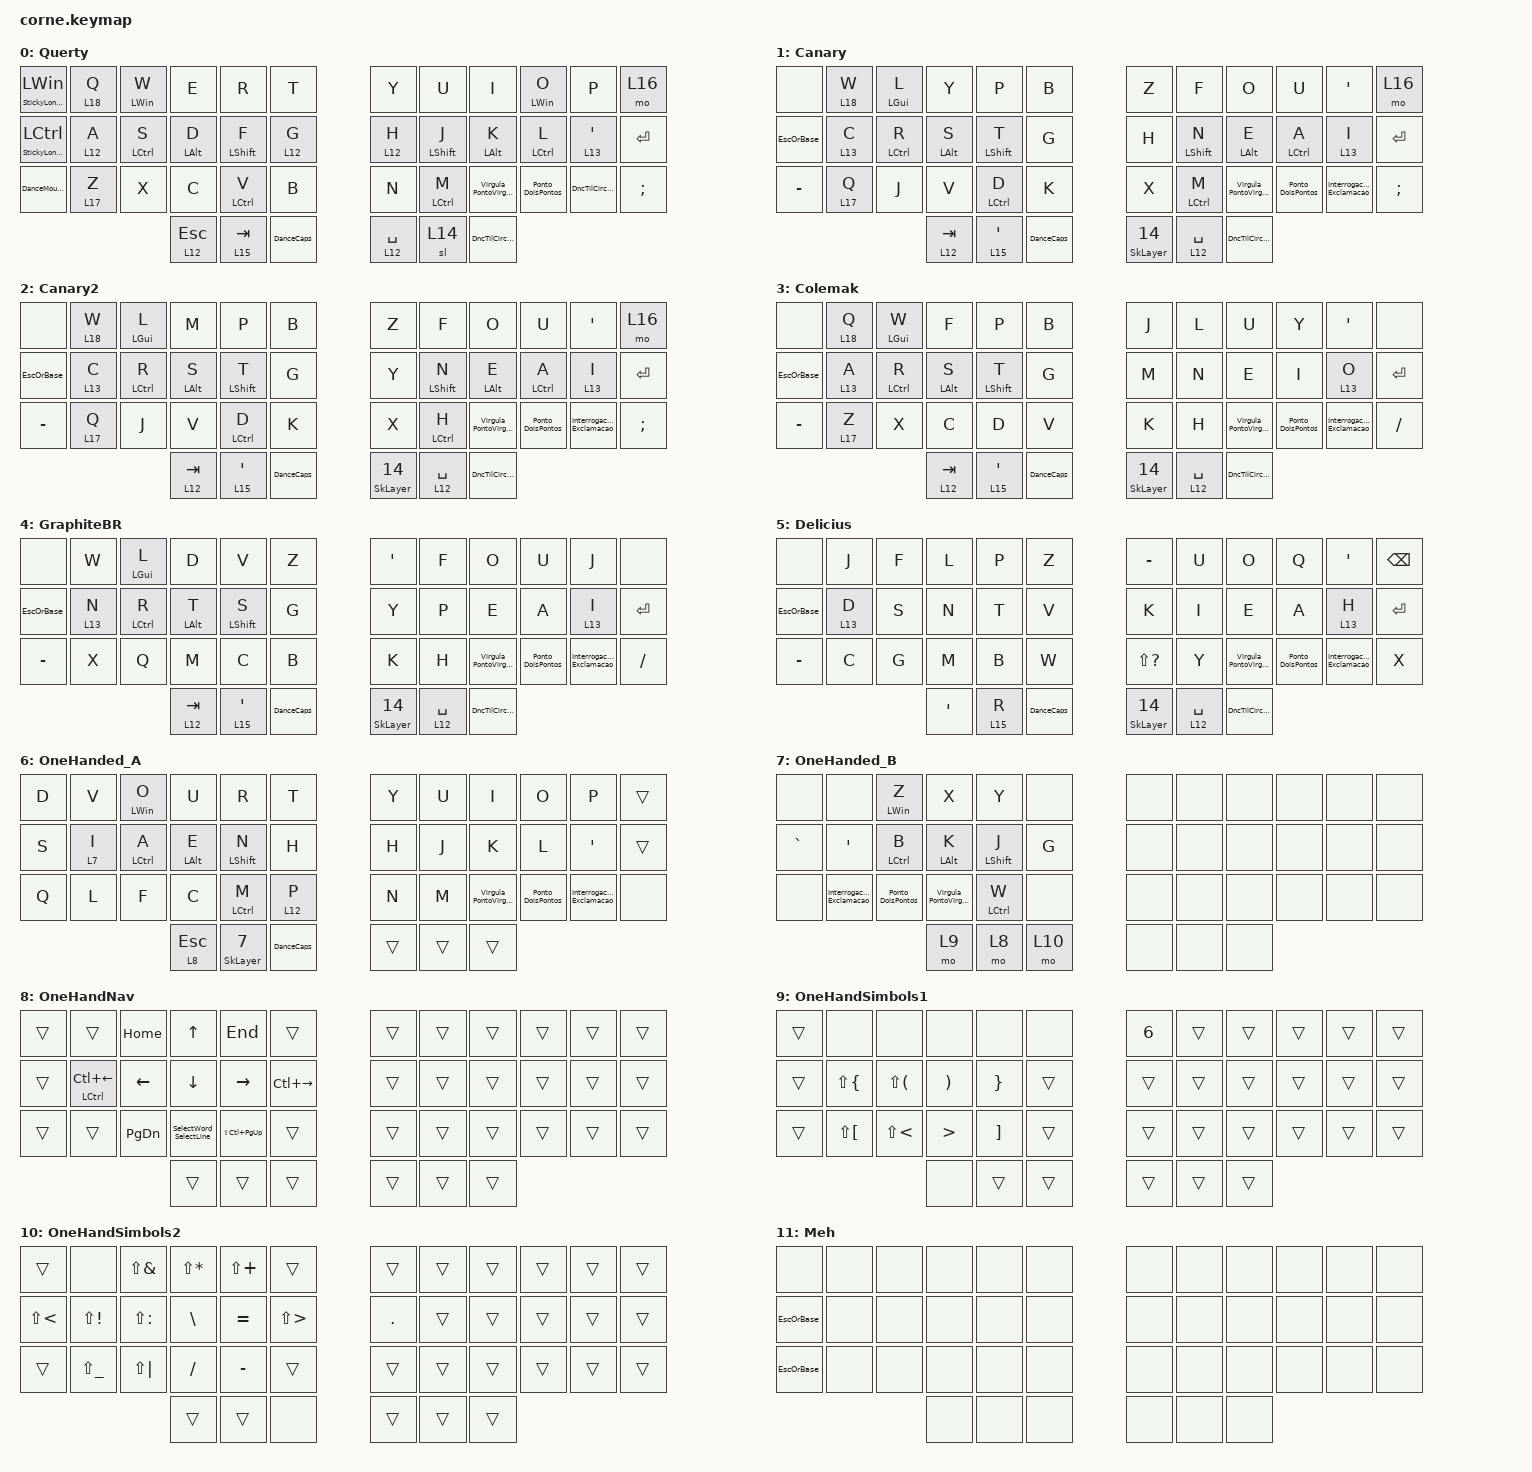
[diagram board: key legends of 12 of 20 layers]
/*
 * Copyright (c) 2020 The ZMK Contributors
 *
 * SPDX-License-Identifier: MIT
 */

#include <dt-bindings/zmk/mouse.h>
#include <behaviors.dtsi>
#include <dt-bindings/zmk/bt.h>
#include <dt-bindings/zmk/keys.h>
#include <dt-bindings/zmk/outputs.h>
#include <dt-bindings/zmk/pointing.h>

/ {
    macros {
        select_line: select_line {
            compatible = "zmk,behavior-macro";
            #binding-cells = <0>;
            bindings = <&kp HOME &kp LS(END)>;
            label = "SELECT_LINE";
            wait-ms = <10>;
            tap-ms = <10>;
        };

        select_left: select_left {
            compatible = "zmk,behavior-macro";
            #binding-cells = <0>;
            bindings = <&kp LC(LEFT) &kp LC(LEFT) &kp LC(LS(RIGHT))>;
            label = "SELECT_LEFT";
            wait-ms = <10>;
            tap-ms = <10>;
        };

        select_right: select_right {
            compatible = "zmk,behavior-macro";
            #binding-cells = <0>;
            bindings = <&kp LC(RIGHT) &kp LC(RIGHT) &kp LC(LS(LEFT))>;
            label = "SELECT_RIGHT";
            wait-ms = <10>;
            tap-ms = <10>;
        };

        Enter_Abaixo: Enter_Abaixo {
            compatible = "zmk,behavior-macro";
            #binding-cells = <0>;
            bindings = <&kp END &kp ENTER>;
            label = "ENTER_ABAIXO";
            wait-ms = <1>;
            tap-ms = <1>;
        };

        Enter_Acima: Enter_Acima {
            compatible = "zmk,behavior-macro";
            #binding-cells = <0>;
            bindings = <&kp HOME &kp ENTER &kp UP_ARROW>;
            label = "ENTER_ACIMA";
            wait-ms = <1>;
            tap-ms = <1>;
        };

        PureCaret: PureCaret {
            compatible = "zmk,behavior-macro";
            #binding-cells = <0>;
            bindings = <&kp CARET &kp SPACE>;
            label = "PURECARET";
            wait-ms = <10>;
            tap-ms = <30>;
        };

        PureSqt: PureSqt {
            compatible = "zmk,behavior-macro";
            #binding-cells = <0>;
            bindings = <&kp SQT &kp SPACE>;
            label = "PURESQT";
            wait-ms = <10>;
            tap-ms = <30>;
        };

        PureQuot: PureQuot {
            compatible = "zmk,behavior-macro";
            #binding-cells = <0>;
            bindings = <&kp DOUBLE_QUOTES &kp SPACE>;
            label = "PUREQUOT";
            wait-ms = <10>;
            tap-ms = <30>;
        };

        PureGrave: PureGrave {
            compatible = "zmk,behavior-macro";
            #binding-cells = <0>;
            bindings = <&kp GRAVE &kp SPACE>;
            label = "PUREGRAVE";
            wait-ms = <10>;
            tap-ms = <30>;
        };

        NumFacil: Easy4Numbers {
            compatible = "zmk,behavior-macro";
            #binding-cells = <0>;
            bindings = <&kp N3 &kp N5 &kp N1 &kp N9>;
            label = "EASY4NUMBERS";
            wait-ms = <10>;
            tap-ms = <30>;
        };

        NumMedio: NumbersMedium {
            compatible = "zmk,behavior-macro";
            #binding-cells = <0>;
            bindings = <&kp N9 &kp N1 &kp N3 &kp N7 &kp N4 &kp N5>;
            label = "NUMBERSMEDIUM";
            wait-ms = <10>;
            tap-ms = <30>;
        };

        NumDificil: NumbersHard {
            compatible = "zmk,behavior-macro";
            #binding-cells = <0>;
            bindings = <&kp N1 &kp N3 &kp N5 &kp N9 &kp N7 &kp N5 &kp N6 &kp N4>;
            label = "NUMBERSHARD";
            wait-ms = <10>;
            tap-ms = <30>;
        };

        AlfaNumFacil: AlfaNumFacil {
            compatible = "zmk,behavior-macro";
            #binding-cells = <0>;
            bindings = <&kp LS(Z) &kp J &kp GRAVE &kp N6 &kp N1 &kp N9>;
            label = "ALFANUMFACIL";
            wait-ms = <10>;
            tap-ms = <30>;
        };

        AlfaNumMedio: AlfaNumMedio {
            compatible = "zmk,behavior-macro";
            #binding-cells = <0>;
            bindings = <&kp Y &kp N1 &kp S &kp LS(A) &kp N1 &kp PRCNT &kp N9 &kp N8>;
            label = "ALFANUMMEDIO";
            wait-ms = <10>;
            tap-ms = <30>;
        };

        AlfaNumDificil: AlfaNumDificil {
            compatible = "zmk,behavior-macro";
            #binding-cells = <0>;
            bindings = <&kp N2 &kp N5 &kp GT &kp LS(I) &kp GT &kp LBRC &kp LT &kp RBRC &kp R &kp N6>;
            label = "ALFANUMDIFICIL";
            wait-ms = <10>;
            tap-ms = <30>;
        };

        AlfaNum1: AlfaNum1 {
            compatible = "zmk,behavior-macro";
            #binding-cells = <0>;
            bindings = <&kp N5 &kp LS(T) &kp N2 &kp N0 &kp N2 &kp N2 &kp AT &kp P &kp K &kp S &kp W>;
            label = "AlfaNum1";
            wait-ms = <10>;
            tap-ms = <20>;
        };

        AlfaNumT: AlfaNumT {
            compatible = "zmk,behavior-macro";
            #binding-cells = <0>;
            bindings = <&kp N5 &kp GT &kp LS(I) &kp O>;
            label = "ALFANUMT";
            wait-ms = <10>;
            tap-ms = <30>;
        };

        AlfaNumR: AlfaNumR {
            compatible = "zmk,behavior-macro";
            #binding-cells = <0>;
            bindings = <&kp U &kp N8 &kp SEMI &kp LS(P)>;
            label = "ALFANUMR";
            wait-ms = <10>;
            tap-ms = <30>;
        };

        AlfaNumF: AlfaNumF {
            compatible = "zmk,behavior-macro";
            #binding-cells = <0>;
            bindings = <&kp LS(P) &kp N6 &kp S &kp CARET>;
            label = "ALFANUMF";
            wait-ms = <10>;
            tap-ms = <30>;
        };

        AlfaNumG: AlfaNumG {
            compatible = "zmk,behavior-macro";
            #binding-cells = <0>;
            bindings = <&kp LS(I) &kp T &kp DOT &kp N7>;
            label = "ALFANUMG";
            wait-ms = <10>;
            tap-ms = <30>;
        };

        AlfaNumV: AlfaNumV {
            compatible = "zmk,behavior-macro";
            #binding-cells = <0>;
            bindings = <&kp N8 &kp LS(L) &kp O &kp EXCL>;
            label = "ALFANUMV";
            wait-ms = <10>;
            tap-ms = <30>;
        };

        AlfaNumB: AlfaNumB {
            compatible = "zmk,behavior-macro";
            #binding-cells = <0>;
            bindings = <&kp N0 &kp A &kp LS(S) &kp UNDER>;
            label = "ALFANUMB";
            wait-ms = <10>;
            tap-ms = <30>;
        };

        PureTilde: PureTilde {
            compatible = "zmk,behavior-macro";
            #binding-cells = <0>;
            bindings = <&kp TILDE &kp SPACE>;
            label = "PURETILDE";
            wait-ms = <10>;
            tap-ms = <10>;
        };

        xxx: xxx {
            compatible = "zmk,behavior-macro-two-param";
            #binding-cells = <2>;
            bindings =
                <&macro_press>,
                <&macro_param_1to1 &mo MACRO_PLACEHOLDER &kp LS(F16)>,
                <&macro_tap>,
                <&macro_pause_for_release>,
                <&macro_release>,
                <&macro_tap>,
                <&macro_param_2to1 &kp MACRO_PLACEHOLDER &kp LS(F15)>;

            label = "XXX";
        };

        vnc: vnc {
            compatible = "zmk,behavior-macro";
            #binding-cells = <0>;
            bindings = <&kp LS(K) &kp N0 &kp N7 &kp V &kp G &kp LS(Z) &kp AT &kp N &kp LS(G) &kp LS(W) &kp LBKT &kp LS(E) &kp K &kp EXCL>;
            label = "VNC";
        };

        CtrlKD: M_CtrlKD {
            compatible = "zmk,behavior-macro";
            #binding-cells = <0>;
            bindings = <&kp LC(K) &kp LC(D) &kp LC(K) &kp LC(E)>;
            label = "M_CTRLKD";
        };

        SelectWord: SelectWord {
            compatible = "zmk,behavior-macro";
            #binding-cells = <0>;
            bindings = <&kp LC(RIGHT) &kp LS(LC(LEFT))>;
            label = "SELECTWORD";
        };

        Cedilha_Maiusculo: Cedilha_Maiusculo {
            compatible = "zmk,behavior-macro";
            #binding-cells = <0>;
            bindings = <&kp SQT &kp LS(C)>;
            label = "CEDILHA_MAIUSCULO";
        };

        Cedilha_Minusculo: Cedilha_Minusculo {
            compatible = "zmk,behavior-macro";
            #binding-cells = <0>;
            bindings = <&kp SQT &kp C>;
            label = "CEDILHA_MINUSCULO";
        };

        SC: SC {
            compatible = "zmk,behavior-macro";
            #binding-cells = <0>;
            bindings = <&kp S &kp C>;
            label = "SC";
        };

        TH: TH {
            compatible = "zmk,behavior-macro";
            #binding-cells = <0>;
            bindings = <&kp T &kp H>;
            label = "TH";
        };

        LH: LH {
            compatible = "zmk,behavior-macro";
            #binding-cells = <0>;
            bindings = <&kp L &kp H>;
            label = "LH";
        };

        CH: CH {
            compatible = "zmk,behavior-macro";
            #binding-cells = <0>;
            bindings = <&kp C &kp H>;
            label = "CH";
        };

        NH: NH {
            compatible = "zmk,behavior-macro";
            #binding-cells = <0>;
            bindings = <&kp N &kp H>;
            label = "NH";
        };

        SH: SH {
            compatible = "zmk,behavior-macro";
            #binding-cells = <0>;
            bindings = <&kp S &kp H>;
            label = "SH";
        };

        QU: QU {
            compatible = "zmk,behavior-macro";
            #binding-cells = <0>;
            bindings = <&kp Q &kp U>;
            label = "QU";
        };
    };

    behaviors {
        HoldLeft: HoldLeft {
            compatible = "zmk,behavior-hold-tap";
            label = "HOLDLEFT";
            bindings = <&kp>, <&kp>;

            #binding-cells = <2>;
            tapping-term-ms = <250>;
            quick-tap-ms = <250>;
            flavor = "tap-preferred";
            require-prior-idle-ms = <200>;
            hold-trigger-on-release;
            hold-trigger-key-positions = <36 37 38 39 40 41 30 18 7 6 19 31 32 33 34 35 11 23 22 21 20 8 9 10 13 14 15 16 24 25 26 27 28 29 0 1 2 3 4 5 14 15 16 17 12>;
        };

        HoldRight: HoldRight {
            compatible = "zmk,behavior-hold-tap";
            label = "HOLDRIGHT";
            bindings = <&kp>, <&kp>;

            #binding-cells = <2>;
            tapping-term-ms = <250>;
            quick-tap-ms = <250>;
            flavor = "tap-preferred";
            require-prior-idle-ms = <150>;
            hold-trigger-key-positions = <38 37 36 29 0 1 2 3 4 5 12 13 14 15 16 17 24 25 26 27 28 22 21 20 19 6 7 8 9 10 11 18 19 20 21 22 23 30 31 32 33 34 35 40 41 39>;
            hold-trigger-on-release;
        };

        StickyKp: StickyKp {
            compatible = "zmk,behavior-sticky-key";
            label = "STICKYKP";
            bindings = <&kp>;
            #binding-cells = <1>;
            release-after-ms = <1000>;
            quick-release;
            ignore-modifiers;
        };

        SkLayer: SkLayer {
            compatible = "zmk,behavior-sticky-key";
            label = "SKLAYER";
            bindings = <&mo>;
            #binding-cells = <1>;
            release-after-ms = <1000>;
            quick-release;
            ignore-modifiers;
        };

        CapsFrase: CapsFrase {
            compatible = "zmk,behavior-caps-word";
            label = "CAPSFRASE";
            #binding-cells = <0>;
            mods = <(MOD_LSFT)>;
            continue-list = <A B C D E F G H I J K L M N O P Q R S T U V W X Y Z SPACE TILDE CARET GRAVE SINGLE_QUOTE BACKSPACE UNDERSCORE MINUS>;
        };

        CapsPalavra: CapsPalavra {
            compatible = "zmk,behavior-caps-word";
            label = "CAPSPALAVRA";
            #binding-cells = <0>;
            mods = <(MOD_LSFT)>;
            continue-list = <A B C D E F G H I J K L M N O P Q R S T U V W X Y Z TILDE CARET GRAVE SINGLE_QUOTE BACKSPACE UNDERSCORE MINUS>;
        };

        DanceCaps: DanceCaps {
            compatible = "zmk,behavior-tap-dance";
            label = "DANCECAPS";
            #binding-cells = <0>;
            bindings = <&StickyKp LSHIFT>, <&CapsPalavra>, <&CapsFrase>;

            tapping-term-ms = <300>;
        };

        EscOrBase: EscOrBase {
            compatible = "zmk,behavior-tap-dance";
            label = "ESCORBASE";
            #binding-cells = <0>;
            bindings = <&kp ESCAPE>, <&to 0>;

            tapping-term-ms = <300>;
        };

        Virgula_PontoVirgula: Virgula_PontoVirgula {
            compatible = "zmk,behavior-mod-morph";
            label = "VIRGULA_PONTOVIRGULA";
            bindings = <&kp COMMA>, <&kp SEMICOLON>;

            #binding-cells = <0>;
            mods = <(MOD_LSFT|MOD_RSFT)>;
        };

        Ponto_DoisPontos: Ponto_DoisPontos {
            compatible = "zmk,behavior-mod-morph";
            label = "PONTO_DOISPONTOS";
            bindings = <&kp PERIOD>, <&kp COLON>;

            #binding-cells = <0>;
            mods = <(MOD_LSFT|MOD_RSFT)>;
        };

        Interrogacao_Exclamacao: Interrogacao_Exclamacao {
            compatible = "zmk,behavior-mod-morph";
            label = "INTERROGACAO_EXCLAMACAO";
            bindings = <&kp QUESTION>, <&kp EXCLAMATION>;

            #binding-cells = <0>;
            mods = <(MOD_LSFT|MOD_RSFT)>;
        };

        HoldLayer: HoldLayer {
            compatible = "zmk,behavior-hold-tap";
            label = "HOLDLAYER";
            bindings = <&mo>, <&kp>;

            #binding-cells = <2>;
            tapping-term-ms = <250>;
            quick-tap-ms = <250>;
            require-prior-idle-ms = <200>;
            flavor = "tap-preferred";
            hold-trigger-key-positions = <0 1 2 3 4 5 6 7 8 9 10 11 12 13 14 15 16 17 18 19 20 21 22 23 24 25 26 27 28 29 30 31 32 33 34 35 36 37 38 39 40 41>;
            hold-trigger-on-release;
        };

        Barra_BarraInvertida: Barra_BarraInvertida {
            compatible = "zmk,behavior-mod-morph";
            label = "BARRA_BARRAINVERTIDA";
            bindings = <&kp SLASH>, <&kp BACKSLASH>;

            #binding-cells = <0>;
            mods = <(MOD_LSFT|MOD_RSFT)>;
        };

        HoldFast: HoldFast {
            compatible = "zmk,behavior-hold-tap";
            label = "HOLDFAST";
            bindings = <&kp>, <&kp>;

            #binding-cells = <2>;
            tapping-term-ms = <150>;
            quick-tap-ms = <150>;
            flavor = "tap-preferred";
            require-prior-idle-ms = <100>;
            hold-trigger-on-release;
        };

        DncTilCircunflexo: DncTilCircunflexo {
            compatible = "zmk,behavior-tap-dance";
            label = "DNCTILCIRCUNFLEXO";
            #binding-cells = <0>;
            bindings = <&kp TILDE>, <&kp CARET>, <&kp GRAVE>;

            tapping-term-ms = <300>;
        };

        SelectWord_SelectLine: SelectWord_SelectLine {
            compatible = "zmk,behavior-tap-dance";
            label = "SELECTWORD_SELECTLINE";
            #binding-cells = <0>;
            tapping-term-ms = <250>;
            bindings = <&SelectWord>, <&select_line>;
        };

        StickyLongoKp: StickyLongoKp {
            compatible = "zmk,behavior-sticky-key";
            label = "STICKYLONGOKP";
            bindings = <&kp>;
            #binding-cells = <1>;
            release-after-ms = <2000>;
            quick-release;
            ignore-modifiers;
        };

        Cedilha: Cedilha {
            compatible = "zmk,behavior-mod-morph";
            label = "CEDILHA";
            bindings = <&Cedilha_Minusculo>, <&Cedilha_Maiusculo>;

            #binding-cells = <0>;
            mods = <(MOD_LSFT)>;
        };

        DanceMouseLayers: DanceMouseLayers {
            compatible = "zmk,behavior-tap-dance";
            label = "DANCEMOUSELAYERS";
            #binding-cells = <0>;
            bindings =
                <&kp LS(LA(LC(A)))>,
                <&kp LS(LA(LC(B)))>,
                <&kp LS(LA(LC(C)))>;

            tapping-term-ms = <300>;
        };
    };

    combos {
        compatible = "zmk,combos";

        PrintScreen {
            bindings = <&kp PRINTSCREEN>;
            key-positions = <0 5>;
            timeout-ms = <50>;
            require-prior-idle-ms = <300>;
        };

        Insert {
            bindings = <&kp INSERT>;
            key-positions = <23 18>;
            timeout-ms = <50>;
            require-prior-idle-ms = <300>;
        };

        Delete1 {
            bindings = <&kp DEL>;
            key-positions = <3 15>;
            timeout-ms = <30>;
            require-prior-idle-ms = <300>;
        };

        Backspace1 {
            bindings = <&kp BACKSPACE>;
            key-positions = <2 14>;
            timeout-ms = <75>;
            require-prior-idle-ms = <300>;
        };

        Backspace2 {
            bindings = <&kp BACKSPACE>;
            key-positions = <8 20>;
            timeout-ms = <30>;
            require-prior-idle-ms = <300>;
        };

        ToLayerConfig {
            bindings = <&mo 16>;
            key-positions = <24 25>;
            timeout-ms = <30>;
            require-prior-idle-ms = <250>;
            layers = <0>;
        };

        ToLayerKeys {
            bindings = <&mo 0>;
            key-positions = <10 9>;
            timeout-ms = <30>;
            require-prior-idle-ms = <300>;
            layers = <0>;
        };

        PreviousTab {
            bindings = <&kp LC(PG_UP)>;
            key-positions = <26 15>;
            timeout-ms = <30>;
        };

        NextTab {
            bindings = <&kp LC(PG_DN)>;
            key-positions = <15 28>;
            timeout-ms = <30>;
        };

        PauseBreak {
            bindings = <&kp PAUSE_BREAK>;
            key-positions = <6 11>;
        };

        ClearBT {
            bindings = <&bt BT_CLR_ALL>;
            key-positions = <12 13>;
            layers = <15>;
        };

        BT1 {
            bindings = <&bt BT_SEL 0>;
            key-positions = <2 3>;
            layers = <15>;
        };

        BT2 {
            bindings = <&bt BT_SEL 1>;
            key-positions = <14 15>;
            layers = <15>;
        };

        BT3 {
            bindings = <&bt BT_SEL 2>;
            key-positions = <26 27>;
            layers = <15>;
        };

        SuperDel {
            bindings = <&kp LC(DEL)>;
            key-positions = <4 16>;
        };

        SuperBackspace {
            bindings = <&kp LC(BACKSPACE)>;
            key-positions = <7 19>;
        };

        ENTER_1 {
            bindings = <&kp ENTER>;
            key-positions = <14 15 16>;
            layers = <0 3 4 5 1 2 6 7>;
        };

        ENTER_2 {
            bindings = <&kp ENTER>;
            key-positions = <19 20 21>;
            layers = <0 3 4 5 1 2>;
        };

        Circunflexo {
            bindings = <&DncTilCircunflexo>;
            key-positions = <5 17>;
        };

        vBckspce {
            bindings = <&kp BACKSPACE>;
            key-positions = <8 20>;
        };

        vCtrlBckspce {
            bindings = <&kp LC(BACKSPACE)>;
            key-positions = <1 13>;
        };

        PontoVirgula {
            bindings = <&kp LC(LS(SEMICOLON))>;
            key-positions = <32 20>;
        };

        CmbSpace {
            bindings = <&kp SPACE>;
            key-positions = <37 38>;
            layers = <6>;
        };

        OneHanded {
            bindings = <&tog 6>;
            key-positions = <36 37 38>;
        };

        CmbSpace2 {
            bindings = <&kp SPACE>;
            key-positions = <26 28 27>;
            layers = <6>;
        };

        CraseCmb {
            bindings = <&kp GRAVE>;
            key-positions = <0 12>;
            layers = <6>;
        };

        CmbSpace3 {
            bindings = <&kp SPACE>;
            key-positions = <31 32 33>;
            layers = <6 7>;
        };

        Combo_ESC {
            bindings = <&kp ESC>;
            key-positions = <16 15 14 13>;
        };
    };

    keymap {
        compatible = "zmk,keymap";

        Querty {
            // -----------------------------------------------------------------------------------------
            // |  TAB |  Q  |  W  |  E  |  R  |  T  |   |  Y  |  U   |  I  |  O  |  P  | BKSP |
            // | CTRL |  A  |  S  |  D  |  F  |  G  |   |  H  |  J   |  K  |  L  |  ;  |  '   |
            // | SHFT |  Z  |  X  |  C  |  V  |  B  |   |  N  |  M   |  ,  |  .  |  /  | ESC  |
            //                    | GUI | LWR | SPC |   | ENT | RSE  | ALT |

            bindings = <
&StickyLongoKp LWIN   &lt 18 Q         &HoldLeft LWIN W   &kp E             &kp R               &kp T              &kp Y            &kp U                &kp I                  &HoldRight LWIN O   &kp P                     &mo 16
&StickyLongoKp LCTRL  &HoldLayer 12 A  &HoldLeft LCTRL S  &HoldLeft LALT D  &HoldLeft LSHIFT F  &HoldLayer 12 G    &HoldLayer 12 H  &HoldRight LSHIFT J  &HoldRight LALT K      &HoldRight LCTRL L  &HoldLayer 13 APOSTROPHE  &kp ENTER
&DanceMouseLayers     &HoldLayer 17 Z  &kp X              &kp C             &HoldLeft LCTRL V   &kp B              &kp N            &HoldRight LCTRL M   &Virgula_PontoVirgula  &Ponto_DoisPontos   &DncTilCircunflexo        &kp SEMICOLON
                                                          &lt 12 ESC        &lt 15 TAB          &DanceCaps         &lt 12 SPACE     &sl 14               &DncTilCircunflexo
            >;

            label = "Querty";
        };

        Canary {
            label = "Canary";
            bindings = <
&none       &HoldLayer 18 W  &HoldLeft LGUI L   &kp Y             &kp P              &kp B         &kp Z        &kp F                &kp O                  &kp U               &kp SINGLE_QUOTE          &mo 16
&EscOrBase  &HoldLayer 13 C  &HoldLeft LCTRL R  &HoldLeft LALT S  &HoldLeft LSHFT T  &kp G         &kp H        &HoldRight LSHIFT N  &HoldRight LALT E      &HoldRight LCTRL A  &HoldLayer 13 I           &kp ENTER
&kp MINUS   &HoldLayer 17 Q  &kp J              &kp V             &HoldLeft LCTRL D  &kp K         &kp X        &HoldRight LCTRL M   &Virgula_PontoVirgula  &Ponto_DoisPontos   &Interrogacao_Exclamacao  &kp SEMICOLON
                                                &lt 12 TAB        &lt 15 SQT         &DanceCaps    &SkLayer 14  &lt 12 SPACE         &DncTilCircunflexo
            >;
        };

        Canary2 {
            label = "Canary2";
            bindings = <
&none       &HoldLayer 18 W  &HoldLeft LGUI L   &kp M             &kp P              &kp B         &kp Z        &kp F                &kp O                  &kp U               &kp SINGLE_QUOTE          &mo 16
&EscOrBase  &HoldLayer 13 C  &HoldLeft LCTRL R  &HoldLeft LALT S  &HoldLeft LSHFT T  &kp G         &kp Y        &HoldRight LSHIFT N  &HoldRight LALT E      &HoldRight LCTRL A  &HoldLayer 13 I           &kp ENTER
&kp MINUS   &HoldLayer 17 Q  &kp J              &kp V             &HoldLeft LCTRL D  &kp K         &kp X        &HoldRight LCTRL H   &Virgula_PontoVirgula  &Ponto_DoisPontos   &Interrogacao_Exclamacao  &kp SEMICOLON
                                                &lt 12 TAB        &lt 15 SQT         &DanceCaps    &SkLayer 14  &lt 12 SPACE         &DncTilCircunflexo
            >;
        };

        Colemak {
            bindings = <
&none       &HoldLayer 18 Q  &HoldLeft LGUI W   &kp F             &kp P              &kp B         &kp J        &kp L         &kp U                  &kp Y              &kp SINGLE_QUOTE          &none
&EscOrBase  &HoldLayer 13 A  &HoldLeft LCTRL R  &HoldLeft LALT S  &HoldLeft LSHFT T  &kp G         &kp M        &kp N         &kp E                  &kp I              &HoldLayer 13 O           &kp ENTER
&kp MINUS   &HoldLayer 17 Z  &kp X              &kp C             &kp D              &kp V         &kp K        &kp H         &Virgula_PontoVirgula  &Ponto_DoisPontos  &Interrogacao_Exclamacao  &kp FSLH
                                                &lt 12 TAB        &lt 15 SQT         &DanceCaps    &SkLayer 14  &lt 12 SPACE  &DncTilCircunflexo
            >;

            label = "Colemak";
        };

        GraphiteBR {
            label = "GraphiteBR";
            bindings = <
&none       &kp W            &HoldLeft LGUI L   &kp D             &kp V              &kp Z         &kp SQT      &kp F         &kp O                  &kp U              &kp J                     &none
&EscOrBase  &HoldLayer 13 N  &HoldLeft LCTRL R  &HoldLeft LALT T  &HoldLeft LSHFT S  &kp G         &kp Y        &kp P         &kp E                  &kp A              &HoldLayer 13 I           &kp ENTER
&kp MINUS   &kp X            &kp Q              &kp M             &kp C              &kp B         &kp K        &kp H         &Virgula_PontoVirgula  &Ponto_DoisPontos  &Interrogacao_Exclamacao  &kp FSLH
                                                &lt 12 TAB        &lt 15 SQT         &DanceCaps    &SkLayer 14  &lt 12 SPACE  &DncTilCircunflexo
            >;
        };

        Delicius {
            label = "Delicius";
            bindings = <
&none       &kp J            &kp F  &kp L    &kp P     &kp Z         &kp MINUS      &kp U         &kp O                  &kp Q              &kp SQT                   &kp BSPC
&EscOrBase  &HoldLayer 13 D  &kp S  &kp N    &kp T     &kp V         &kp K          &kp I         &kp E                  &kp A              &HoldLayer 13 H           &kp ENTER
&kp MINUS   &kp C            &kp G  &kp M    &kp B     &kp W         &kp LS(QMARK)  &kp Y         &Virgula_PontoVirgula  &Ponto_DoisPontos  &Interrogacao_Exclamacao  &kp X
                                    &kp SQT  &lt 15 R  &DanceCaps    &SkLayer 14    &lt 12 SPACE  &DncTilCircunflexo
            >;
        };

        OneHanded_A {
            bindings = <
&kp D  &kp V    &HoldLeft LEFT_WIN O  &kp U                 &kp R                   &kp T         &kp Y   &kp U   &kp I                  &kp O              &kp P                     &trans
&kp S  &lt 7 I  &HoldLeft LCTRL A     &HoldLeft LEFT_ALT E  &HoldLeft LEFT_SHIFT N  &kp H         &kp H   &kp J   &kp K                  &kp L              &kp SQT                   &trans
&kp Q  &kp L    &kp F                 &kp C                 &HoldLeft LCTRL M       &lt 12 P      &kp N   &kp M   &Virgula_PontoVirgula  &Ponto_DoisPontos  &Interrogacao_Exclamacao  &none
                                      &lt 8 ESC             &SkLayer 7              &DanceCaps    &trans  &trans  &trans
            >;

            label = "OneHanded_A";
        };

        OneHanded_B {
            bindings = <
&none      &none                     &HoldLeft LWIN Z   &kp X                  &kp Y               &none     &none  &none  &none  &none  &none  &none
&kp GRAVE  &kp APOS                  &HoldLeft LCTRL B  &HoldLeft LALT K       &HoldLeft LSHIFT J  &kp G     &none  &none  &none  &none  &none  &none
&none      &Interrogacao_Exclamacao  &Ponto_DoisPontos  &Virgula_PontoVirgula  &HoldLeft LCTRL W   &none     &none  &none  &none  &none  &none  &none
                                                        &mo 9                  &mo 8               &mo 10    &none  &none  &none
            >;

            label = "OneHanded_B";
        };

        OneHandNav {
            bindings = <
&trans  &trans                    &kp HOME   &kp UP                  &kp END            &trans           &trans  &trans  &trans  &trans  &trans  &trans
&trans  &HoldLeft LCTRL LC(LEFT)  &kp LEFT   &kp DOWN                &kp RIGHT          &kp LC(RIGHT)    &trans  &trans  &trans  &trans  &trans  &trans
&trans  &trans                    &kp PG_DN  &SelectWord_SelectLine  &kp LS(LC(PG_UP))  &trans           &trans  &trans  &trans  &trans  &trans  &trans
                                             &trans                  &trans             &trans           &trans  &trans  &trans
            >;
        };

        OneHandSimbols1 {
            bindings = <
&trans  &none                 &none                     &none                  &none              &none     &kp N6  &trans  &trans  &trans  &trans  &trans
&trans  &kp LS(LEFT_BRACE)    &kp LS(LEFT_PARENTHESIS)  &kp RIGHT_PARENTHESIS  &kp RIGHT_BRACE    &trans    &trans  &trans  &trans  &trans  &trans  &trans
&trans  &kp LS(LEFT_BRACKET)  &kp LS(LESS_THAN)         &kp GREATER_THAN       &kp RIGHT_BRACKET  &trans    &trans  &trans  &trans  &trans  &trans  &trans
                                                        &none                  &trans             &trans    &trans  &trans  &trans
            >;

            label = "OneHandSimbols1";
        };

        OneHandSimbols2 {
            bindings = <
&trans      &none          &kp LS(AMPS)   &kp LS(STAR)  &kp LS(PLUS)  &trans        &trans   &trans  &trans  &trans  &trans  &trans
&kp LS(LT)  &kp LS(EXCL)   &kp LS(COLON)  &kp BSLH      &kp EQUAL     &kp LS(GT)    &kp DOT  &trans  &trans  &trans  &trans  &trans
&trans      &kp LS(UNDER)  &kp LS(PIPE)   &kp FSLH      &kp MINUS     &trans        &trans   &trans  &trans  &trans  &trans  &trans
                                          &trans        &trans        &none         &trans   &trans  &trans
            >;
        };

        Meh {
            bindings = <
&none       &none  &none  &none  &none  &none    &none  &none  &none  &none  &none  &none
&EscOrBase  &none  &none  &none  &none  &none    &none  &none  &none  &none  &none  &none
&EscOrBase  &none  &none  &none  &none  &none    &none  &none  &none  &none  &none  &none
                          &none  &none  &none    &none  &none  &none
            >;

            label = "Meh";
        };

        NavRight {
            label = "NavRight";
            bindings = <
&trans  &none    &HoldLeft LWIN F7   &kp F8             &kp F9              &none                    &none         &kp HOME      &kp UP                  &kp END        &none          &EscOrBase
&trans  &kp F10  &HoldLeft LCTRL F4  &HoldLeft LALT F5  &HoldLeft LSHFT F6  &HoldFast LC(F12) F12    &kp LC(LEFT)  &kp LEFT      &kp DOWN                &kp RIGHT      &kp LC(RIGHT)  &kp ENTER
&trans  &kp F11  &kp F1              &kp F2             &kp F3              &none                    &kp PG_UP     &select_left  &SelectWord_SelectLine  &select_right  &kp PG_DN      &kp ENTER
                                     &kp LS(F3)         &kp F2              &DanceCaps               &DanceCaps    &kp SPACE     &none
            >;
        };

        NavLeft {
            bindings = <
&trans  &none  &HoldLeft HOME PG_UP  &kp UP               &HoldLeft END PAGE_DOWN  &none         &none                  &kp N7               &kp N8              &kp N9               &none  &EscOrBase
&trans  &none  &HoldLeft LCTRL LEFT  &HoldLeft LALT DOWN  &HoldLeft LSHIFT RIGHT   &none         &none                  &HoldRight LSHFT N4  &HoldRight LALT N5  &HoldRight LCTRL N6  &none  &kp ENTER
&trans  &none  &kp LC(PG_UP)         &mkp MB1             &kp LC(PG_DN)            &none         &none                  &kp N1               &kp N2              &kp N3               &none  &kp ENTER
                                     &none                &kp SPACE                &DanceCaps    &HoldRight LWIN COMMA  &kp N0               &kp DOT
            >;

            label = "NavLeft";
        };

        Simbolos {
            bindings = <
&trans  &kp LS(EXCL)  &kp LS(AT)    &kp LS(POUND)  &kp LS(DLLR)  &kp LS(PRCNT)    &kp SQT       &kp SQT       &kp GRAVE      &kp DQT        &kp DQT       &none
&trans  &kp LS(LPAR)  &kp LS(LBRC)  &kp LS(COLON)  &kp LS(RBRC)  &kp LS(RPAR)     &kp LBKT      &kp LS(LT)    &kp EQUAL      &kp LS(GT)     &kp RBKT      &none
&none   &kp FSLH      &kp MINUS     &kp BSLH       &kp LS(PLUS)  &kp LS(STAR)     &kp LS(AMPS)  &kp LS(EXCL)  &kp LS(UNDER)  &kp LS(QMARK)  &kp LS(PIPE)  &none
                                    &none          &none         &DanceCaps       &SkLayer 14   &kp SPACE     &none
            >;

            label = "Simbolos";
        };

        Atalhos {
            bindings = <
&kp LG(N1)                       &kp LC(Y)    &HoldFast LC(F4) LC(W)     &kp LG(E)   &HoldFast LC(F5) F5  &mkp MB4                             &kp LS(LA(LC(Y)))  &kp C_MUTE  &kp C_PREVIOUS  &kp C_NEXT  &kp C_PLAY_PAUSE  &kp C_VOLUME_UP
&HoldFast LG(LS(LEFT)) LG(LEFT)  &kp LS(TAB)  &HoldFast LC(LS(S)) LC(S)  &kp LS(F3)  &kp TAB              &HoldFast LG(LS(RIGHT)) LG(RIGHT)    &kp LS(LA(LC(H)))  &none       &CtrlKD         &none       &none             &kp C_VOLUME_DOWN
&kp LG(N3)                       &kp LC(Z)    &kp LC(X)                  &kp LC(C)   &kp LC(V)            &kp LC(Y)                            &kp LS(LA(LC(N)))  &none       &none           &none       &none             &none
                                                                         &none       &none                &none                                &kp LSHIFT         &kp SPACE   &none
            >;

            label = "Atalhos";
        };

        Config {
            bindings = <
&out OUT_BLE  &out OUT_USB  &none         &none         &bt BT_CLR    &bt BT_CLR_ALL    &none        &to 2  &to 1  &to 4  &to 3  &none
&EscOrBase    &bt BT_SEL 0  &bt BT_SEL 1  &bt BT_SEL 2  &bt BT_SEL 3  &bt BT_SEL 4      &none        &none  &none  &none  &none  &none
&EscOrBase    &none         &none         &none         &none         &bootloader       &bootloader  &none  &none  &none  &none  &none
                                          &none         &none         &none             &none        &none  &none
            >;

            label = "CFG";
        };

        Janelas {
            bindings = <
&none    &none  &none                            &none                          &none                              &none                &none  &none      &none  &none  &none  &EscOrBase
&kp ESC  &none  &HoldFast LG(LS(LEFT)) LG(LEFT)  &HoldFast LA(LS(TAB)) LA(TAB)  &HoldFast LG(LS(RIGHT)) LG(RIGHT)  &none                &none  &none      &none  &none  &none  &kp ENTER
&none    &none  &kp LG(NUMBER_1)                 &kp LG(NUMBER_2)               &kp LG(NUMBER_3)                   &none                &none  &none      &none  &none  &none  &none
                                                 &none                          &kp LG(LC(LEFT))                   &kp LG(LC(RIGHT))    &none  &kp SPACE  &none
            >;

            label = "Janelas";
        };

        Keys {
            bindings = <
&none       &NumFacil    &AlfaNumFacil    &AlfaNum1  &AlfaNumR  &AlfaNumT    &none  &none  &none  &none  &none  &none
&EscOrBase  &NumMedio    &AlfaNumMedio    &vnc       &AlfaNumF  &AlfaNumG    &none  &none  &none  &none  &none  &none
&EscOrBase  &NumDificil  &AlfaNumDificil  &none      &AlfaNumV  &AlfaNumB    &none  &none  &none  &none  &none  &none
                                          &none      &none      &none        &none  &none  &none
            >;

            label = "Keys";
        };

        Hyper {
            bindings = <
&none       &none  &none  &none  &none  &none    &none  &none  &none  &none  &none  &none
&EscOrBase  &none  &none  &none  &none  &none    &none  &none  &none  &none  &none  &none
&EscOrBase  &none  &none  &none  &none  &none    &none  &none  &none  &none  &none  &none
                          &none  &none  &none    &none  &none  &none
            >;

            label = "Hyper";
        };
    };
};
